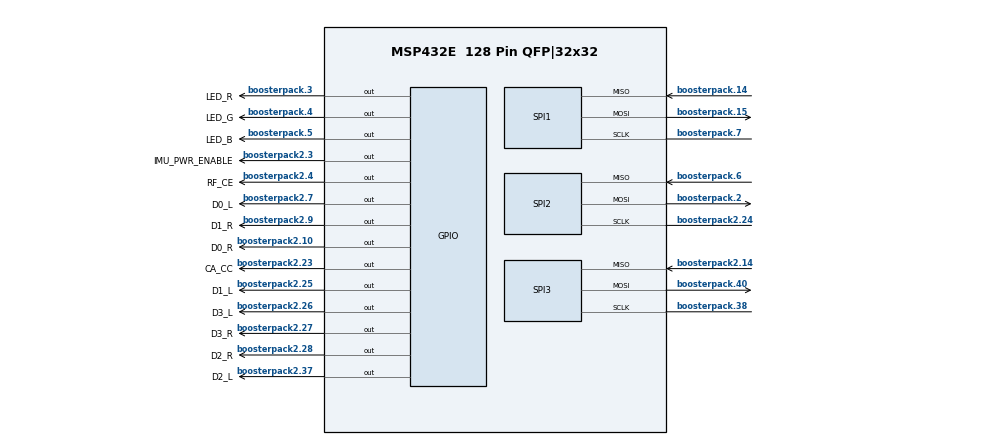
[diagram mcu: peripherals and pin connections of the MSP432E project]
/**
 * @cliArgs --board "/ti/boards/MSP_EXP432E401Y" --device "MSP432E" --part "MSP432E401YTPDT" --package "128 Pin QFP|32x32" --product "simplelink_msp432e4_sdk@4.20.00.12"
 * @versions {"tool":"1.24.1+4189"}
 */

/**
 * Import the modules used in this configuration.
 */
const GPIO   = scripting.addModule("/ti/drivers/GPIO", {}, false);
const GPIO1  = GPIO.addInstance();
const GPIO2  = GPIO.addInstance();
const GPIO3  = GPIO.addInstance();
const GPIO4  = GPIO.addInstance();
const GPIO5  = GPIO.addInstance();
const GPIO6  = GPIO.addInstance();
const GPIO7  = GPIO.addInstance();
const GPIO8  = GPIO.addInstance();
const GPIO9  = GPIO.addInstance();
const GPIO10 = GPIO.addInstance();
const GPIO11 = GPIO.addInstance();
const GPIO12 = GPIO.addInstance();
const GPIO13 = GPIO.addInstance();
const GPIO14 = GPIO.addInstance();
const I2C    = scripting.addModule("/ti/drivers/I2C", {}, false);
const I2C1   = I2C.addInstance();
const SPI    = scripting.addModule("/ti/drivers/SPI", {}, false);
const SPI1   = SPI.addInstance();
const SPI2   = SPI.addInstance();
const SPI3   = SPI.addInstance();

/**
 * Write custom configuration values to the imported modules.
 */
GPIO1.$name           = "D3_R";
GPIO1.gpioPin.$assign = "boosterpack2.27";

GPIO2.$name           = "D2_R";
GPIO2.gpioPin.$assign = "boosterpack2.28";

GPIO3.$name           = "D1_R";
GPIO3.gpioPin.$assign = "boosterpack2.9";

GPIO4.$name           = "D0_R";
GPIO4.gpioPin.$assign = "boosterpack2.10";

GPIO5.$name           = "D3_L";
GPIO5.gpioPin.$assign = "boosterpack2.26";

GPIO6.$name           = "D2_L";
GPIO6.gpioPin.$assign = "boosterpack2.37";

GPIO7.$name           = "D1_L";
GPIO7.gpioPin.$assign = "boosterpack2.25";

GPIO8.$name           = "D0_L";
GPIO8.gpioPin.$assign = "boosterpack2.7";

GPIO9.$name           = "IMU_PWR_ENABLE";
GPIO9.gpioPin.$assign = "boosterpack2.3";

GPIO10.$name           = "RF_CE";
GPIO10.gpioPin.$assign = "boosterpack2.4";

GPIO11.$name           = "LED_R";
GPIO11.gpioPin.$assign = "boosterpack.3";

GPIO12.$name           = "LED_G";
GPIO12.gpioPin.$assign = "boosterpack.4";

GPIO13.$name           = "LED_B";
GPIO13.gpioPin.$assign = "boosterpack.5";

GPIO14.$name           = "CA_CC";
GPIO14.gpioPin.$assign = "boosterpack2.23";

I2C1.$name = "CONFIG_I2C_0";

SPI1.$name               = "SPI_L_MOTOR";
SPI1.spi.sclkPin.$assign = "boosterpack.7";
SPI1.spi.misoPin.$assign = "boosterpack.14";
SPI1.spi.mosiPin.$assign = "boosterpack.15";

SPI2.$name               = "SPI_R_MOTOR";
SPI2.spi.sclkPin.$assign = "boosterpack2.24";
SPI2.spi.misoPin.$assign = "boosterpack.6";
SPI2.spi.mosiPin.$assign = "boosterpack.2";

SPI3.$name               = "SPI_RF";
SPI3.spi.sclkPin.$assign = "boosterpack.38";
SPI3.spi.misoPin.$assign = "boosterpack2.14";
SPI3.spi.mosiPin.$assign = "boosterpack.40";

/**
 * Pinmux solution for unlocked pins/peripherals. This ensures that minor changes to the automatic solver in a future
 * version of the tool will not impact the pinmux you originally saw.  These lines can be completely deleted in order to
 * re-solve from scratch.
 */
I2C1.i2c.$suggestSolution              = "I2C1";
I2C1.i2c.sdaPin.$suggestSolution       = "boosterpack2.40";
I2C1.i2c.sclPin.$suggestSolution       = "boosterpack.37";
SPI1.spi.$suggestSolution              = "SSI2";
SPI1.spi.dmaRxChannel.$suggestSolution = "UDMA_CH12";
SPI1.spi.dmaTxChannel.$suggestSolution = "UDMA_CH13";
SPI2.spi.$suggestSolution              = "SSI1";
SPI2.spi.dmaRxChannel.$suggestSolution = "UDMA_CH10";
SPI2.spi.dmaTxChannel.$suggestSolution = "UDMA_CH11";
SPI3.spi.$suggestSolution              = "SSI3";
SPI3.spi.dmaRxChannel.$suggestSolution = "UDMA_CH14";
SPI3.spi.dmaTxChannel.$suggestSolution = "UDMA_CH15";
